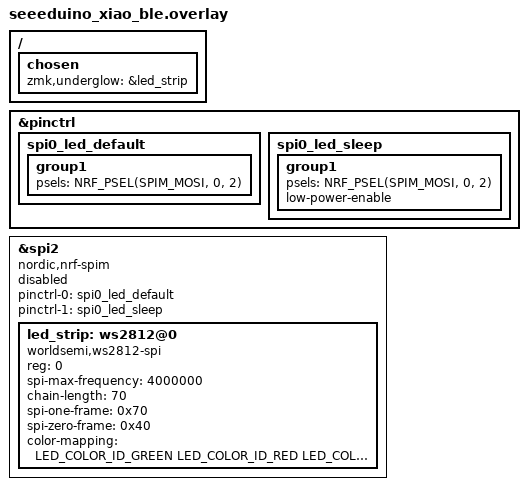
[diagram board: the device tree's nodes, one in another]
#include <dt-bindings/led/led.h>

&pinctrl {
    spi0_led_default: spi0_led_default {
        group1 {
            psels = <NRF_PSEL(SPIM_MOSI, 0, 2)>;  // Changed to P0.02
        };
    };

    spi0_led_sleep: spi0_led_sleep {
        group1 {
            psels = <NRF_PSEL(SPIM_MOSI, 0, 2)>;  // Changed to P0.02
            low-power-enable;
        };
    };
};

&spi2 {
    compatible = "nordic,nrf-spim";
    status = "disabled";

    pinctrl-0 = <&spi0_led_default>;
    pinctrl-1 = <&spi0_led_sleep>;
    pinctrl-names = "default", "sleep";

    led_strip: ws2812@0 {
        compatible = "worldsemi,ws2812-spi";
        // label = "WS2812";

        /* SPI */
        reg = <0>; /* ignored, but necessary for SPI bindings */
        spi-max-frequency = <4000000>;

        /* WS2812 */
        chain-length = <70>; /* arbitrary; change at will */
        spi-one-frame = <0x70>;
        spi-zero-frame = <0x40>;

        color-mapping = <LED_COLOR_ID_GREEN LED_COLOR_ID_RED LED_COLOR_ID_BLUE>;
    };
};

/ {
    // led_strip: ws2812 {
    //     compatible = "worldsemi,ws2812-gpio";
    //     chain-length = <38>; // Keep low for testing
    //     color-mapping = <LED_COLOR_ID_GREEN LED_COLOR_ID_RED LED_COLOR_ID_BLUE>;
        
    //     // Use bit-banging on Nice Nano
    //     in-gpios = <&gpio0 2 GPIO_ACTIVE_HIGH>;
    //     reset-delay = <280>;
    // };


    chosen {
        zmk,underglow = &led_strip;
    };
};
